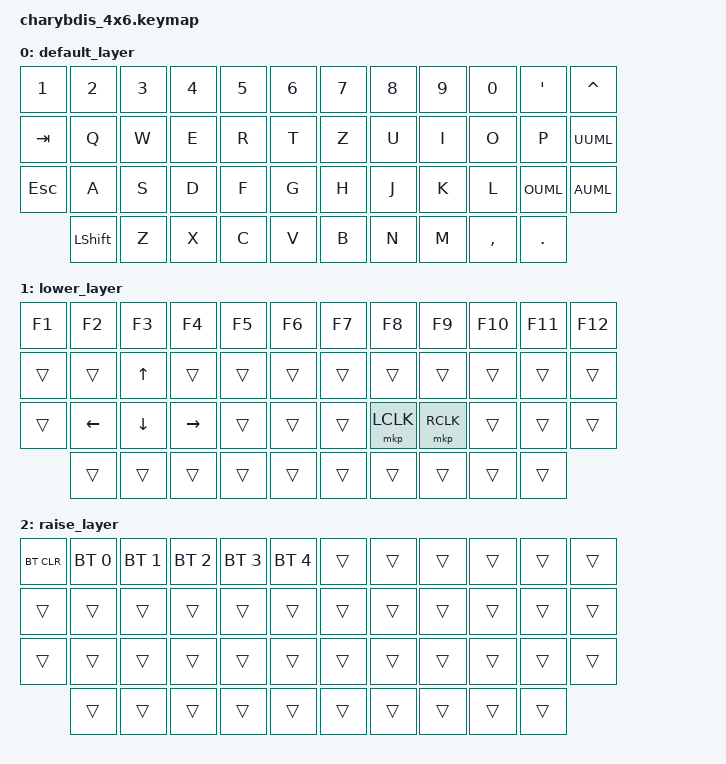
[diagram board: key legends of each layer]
#include <behaviors.dtsi>
#include <dt-bindings/zmk/keys.h>
#include <dt-bindings/zmk/bt.h>
#include <dt-bindings/zmk/outputs.h>
#include <dt-bindings/zmk/mouse.h>

// Layer definitions
#define DEFAULT 0
#define LOWER   1
#define RAISE   2
#define ADJUST  3

/ {
    behaviors {
        // Mouse movement behavior
        mmt: mouse_move_trigger {
            compatible = "zmk,behavior-mouse-move-tap";
            label = "MOUSE_MOVE_TAP";
            #binding-cells = <2>;
            tapping-term-ms = <200>;
            bindings = <&mmv>, <&mkp>;
        };
    };

    keymap {
        compatible = "zmk,keymap";

        default_layer {
            bindings = 
                &kp N1    &kp N2    &kp N3     &kp N4     &kp N5     &kp N6          &kp N7     &kp N8     &kp N9     &kp N0     &kp SQT    &kp CARET
                &kp TAB   &kp Q     &kp W      &kp E      &kp R      &kp T           &kp Z      &kp U      &kp I      &kp O      &kp P      &kp UUML
                &kp ESC   &kp A     &kp S      &kp D      &kp F      &kp G           &kp H      &kp J      &kp K      &kp L      &kp OUML   &kp AUML
                         &kp LSHFT  &kp Z      &kp X      &kp C      &kp V           &kp B      &kp N      &kp M     &kp COMMA  &kp DOT
            >;

            sensor-bindings = <&mmv SCROLL_UP SCROLL_DOWN>;
        };

        lower_layer {
            bindings = 
                &kp F1    &kp F2    &kp F3     &kp F4     &kp F5     &kp F6          &kp F7     &kp F8     &kp F9     &kp F10    &kp F11    &kp F12
                &trans    &trans    &kp UP     &trans     &trans     &trans          &trans     &trans     &trans     &trans     &trans     &trans
                &trans    &kp LEFT  &kp DOWN   &kp RIGHT  &trans     &trans          &trans     &mkp LCLK  &mkp RCLK  &trans     &trans     &trans
                         &trans    &trans     &trans     &trans     &trans          &trans     &trans     &trans     &trans     &trans
            >;

            sensor-bindings = <&mmv MOVE_HOR MOVE_VERT>;
        };

        raise_layer {
            bindings = 
                &bt BT_CLR &bt BT_SEL 0 &bt BT_SEL 1 &bt BT_SEL 2 &bt BT_SEL 3 &bt BT_SEL 4    &trans     &trans     &trans     &trans     &trans     &trans
                &trans     &trans       &trans       &trans       &trans       &trans          &trans     &trans     &trans     &trans     &trans     &trans
                &trans     &trans       &trans       &trans       &trans       &trans          &trans     &trans     &trans     &trans     &trans     &trans
                          &trans       &trans       &trans       &trans       &trans          &trans     &trans     &trans     &trans     &trans
            >;

            sensor-bindings = <&mmv MOVE_HOR MOVE_VERT>;
        };
    };
};
